# CY8C5888LTI_LP097 register map
File version: 0.1
CY8C58LP
Registers are 8-bit, read-write, no defined reset value unless marked. A register's access mark holds for its fields unless they carry their own. Offsets are from the block's base; lines under a group give offsets from that group; [hi:lo] are bit positions; {n}, {i} and the like mark numbered series; 'fields as' and 'values as' point back to an identical list; <NAME> marks a mode.

## Memory map
0x00000000 ButtonReg6
0x00000000 ButtonReg5
0x00000000 ButtonReg4
0x00000000 ButtonReg1
0x00000000 USBFS_1 — USBFS
0x00000000 ButtonReg3
0x00000000 ButtonReg2

## ButtonReg6
Base 0x00000000
0x40006469 ButtonReg6_STATUS_REG
0x40006489 ButtonReg6_MASK_REG
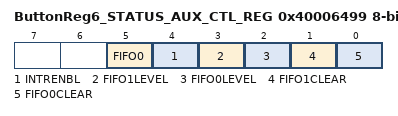
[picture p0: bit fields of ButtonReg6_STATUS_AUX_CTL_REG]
0x40006499 ButtonReg6_STATUS_AUX_CTL_REG
  [5] FIFO0 — FIFO0 clear
    1=ENABLED (Enable counter); 0=DISABLED (Disable counter)
  [4] INTRENBL — Enables or disables the Interrupt
    1=ENABLED (Interrupt enabled); 0=DISABLED (Interrupt disabled)
  [3] FIFO1LEVEL — FIFO level
    1=ENABLED (FIFO LVL: input mode: FIFO at least 1/2 empty; output mode: FIFO at least 1/2 full); 0=DISABLED (FIFO LVL: input mode: FIFO not full; output mode: FIFO not empty)
  [2] FIFO0LEVEL — FIFO level
    values as FIFO1LEVEL
  [1] FIFO1CLEAR — FIFO clear
    1=ENABLED (Clear FIFO state); 0=DISABLED (Normal FIFO operation)
  [0] FIFO0CLEAR — FIFO clear
    values as FIFO1CLEAR

## ButtonReg5
Base 0x00000000
0x40006567 ButtonReg5_STATUS_REG
0x40006587 ButtonReg5_MASK_REG
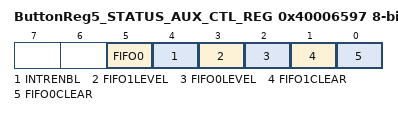
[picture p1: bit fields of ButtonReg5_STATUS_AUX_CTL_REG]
0x40006597 ButtonReg5_STATUS_AUX_CTL_REG
  [5] FIFO0 — FIFO0 clear
    1=ENABLED (Enable counter); 0=DISABLED (Disable counter)
  [4] INTRENBL — Enables or disables the Interrupt
    1=ENABLED (Interrupt enabled); 0=DISABLED (Interrupt disabled)
  [3] FIFO1LEVEL — FIFO level
    1=ENABLED (FIFO LVL: input mode: FIFO at least 1/2 empty; output mode: FIFO at least 1/2 full); 0=DISABLED (FIFO LVL: input mode: FIFO not full; output mode: FIFO not empty)
  [2] FIFO0LEVEL — FIFO level
    values as FIFO1LEVEL
  [1] FIFO1CLEAR — FIFO clear
    1=ENABLED (Clear FIFO state); 0=DISABLED (Normal FIFO operation)
  [0] FIFO0CLEAR — FIFO clear
    values as FIFO1CLEAR

## ButtonReg4
Base 0x00000000
0x40006467 ButtonReg4_STATUS_REG
0x40006487 ButtonReg4_MASK_REG
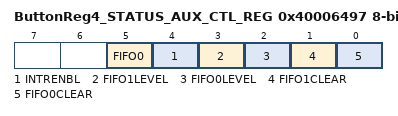
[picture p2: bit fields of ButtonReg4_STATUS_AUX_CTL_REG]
0x40006497 ButtonReg4_STATUS_AUX_CTL_REG
  [5] FIFO0 — FIFO0 clear
    1=ENABLED (Enable counter); 0=DISABLED (Disable counter)
  [4] INTRENBL — Enables or disables the Interrupt
    1=ENABLED (Interrupt enabled); 0=DISABLED (Interrupt disabled)
  [3] FIFO1LEVEL — FIFO level
    1=ENABLED (FIFO LVL: input mode: FIFO at least 1/2 empty; output mode: FIFO at least 1/2 full); 0=DISABLED (FIFO LVL: input mode: FIFO not full; output mode: FIFO not empty)
  [2] FIFO0LEVEL — FIFO level
    values as FIFO1LEVEL
  [1] FIFO1CLEAR — FIFO clear
    1=ENABLED (Clear FIFO state); 0=DISABLED (Normal FIFO operation)
  [0] FIFO0CLEAR — FIFO clear
    values as FIFO1CLEAR

## ButtonReg1
Base 0x00000000
0x40006462 ButtonReg1_STATUS_REG
0x40006482 ButtonReg1_MASK_REG
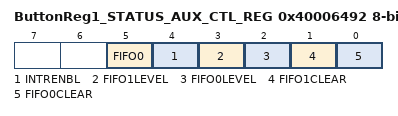
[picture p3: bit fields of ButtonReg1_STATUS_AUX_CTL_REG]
0x40006492 ButtonReg1_STATUS_AUX_CTL_REG
  [5] FIFO0 — FIFO0 clear
    1=ENABLED (Enable counter); 0=DISABLED (Disable counter)
  [4] INTRENBL — Enables or disables the Interrupt
    1=ENABLED (Interrupt enabled); 0=DISABLED (Interrupt disabled)
  [3] FIFO1LEVEL — FIFO level
    1=ENABLED (FIFO LVL: input mode: FIFO at least 1/2 empty; output mode: FIFO at least 1/2 full); 0=DISABLED (FIFO LVL: input mode: FIFO not full; output mode: FIFO not empty)
  [2] FIFO0LEVEL — FIFO level
    values as FIFO1LEVEL
  [1] FIFO1CLEAR — FIFO clear
    1=ENABLED (Clear FIFO state); 0=DISABLED (Normal FIFO operation)
  [0] FIFO0CLEAR — FIFO clear
    values as FIFO1CLEAR

## ButtonReg3
Base 0x00000000
0x40006565 ButtonReg3_STATUS_REG
0x40006585 ButtonReg3_MASK_REG
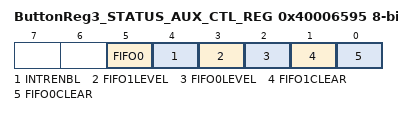
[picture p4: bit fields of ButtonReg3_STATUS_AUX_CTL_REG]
0x40006595 ButtonReg3_STATUS_AUX_CTL_REG
  [5] FIFO0 — FIFO0 clear
    1=ENABLED (Enable counter); 0=DISABLED (Disable counter)
  [4] INTRENBL — Enables or disables the Interrupt
    1=ENABLED (Interrupt enabled); 0=DISABLED (Interrupt disabled)
  [3] FIFO1LEVEL — FIFO level
    1=ENABLED (FIFO LVL: input mode: FIFO at least 1/2 empty; output mode: FIFO at least 1/2 full); 0=DISABLED (FIFO LVL: input mode: FIFO not full; output mode: FIFO not empty)
  [2] FIFO0LEVEL — FIFO level
    values as FIFO1LEVEL
  [1] FIFO1CLEAR — FIFO clear
    1=ENABLED (Clear FIFO state); 0=DISABLED (Normal FIFO operation)
  [0] FIFO0CLEAR — FIFO clear
    values as FIFO1CLEAR
